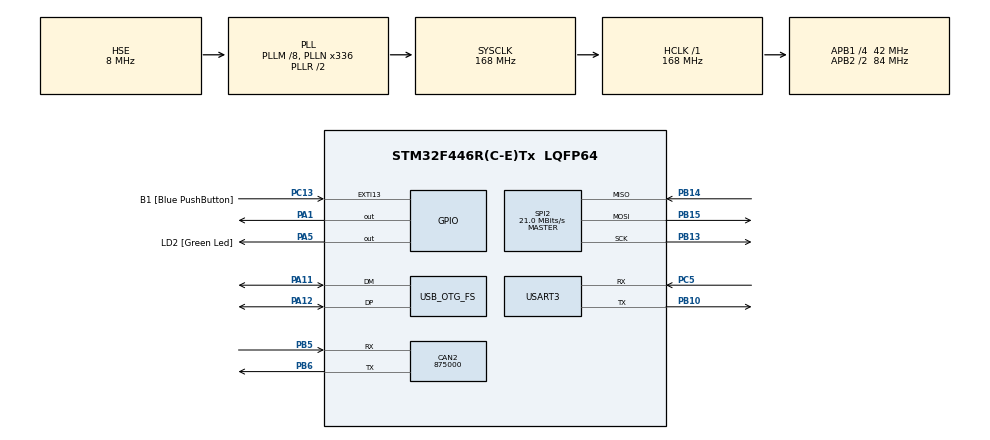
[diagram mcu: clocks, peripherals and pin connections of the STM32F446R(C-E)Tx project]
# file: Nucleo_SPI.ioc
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CAN2.CalculateBaudRate=875000
CAN2.CalculateTimeBit=1142
CAN2.CalculateTimeQuantum=380.95238095238096
Mcu.Family=STM32F4
Mcu.Name=STM32F446R(C-E)Tx
Mcu.Package=LQFP64
NVIC.PriorityGroup=NVIC_PRIORITYGROUP_0
PA1.Signal=GPIO_Output
PA11.Mode=Device_Only
PA11.Signal=USB_OTG_FS_DM
PA12.Mode=Device_Only
PA12.Signal=USB_OTG_FS_DP
PA13.GPIO_Label=TMS
PA13.Mode=Serial_Wire
PA13.Signal=SYS_JTMS-SWDIO
PA14.GPIO_Label=TCK
PA14.Mode=Serial_Wire
PA14.Signal=SYS_JTCK-SWCLK
PA2.GPIO_Label=USART_TX
PA2.Signal=USART2_TX
PA3.GPIO_Label=USART_RX
PA3.Signal=USART2_RX
PA5.GPIO_Label=LD2 [Green Led]
PA5.Signal=GPIO_Output
PB10.Mode=Asynchronous
PB10.Signal=USART3_TX
PB13.Mode=Full_Duplex_Master
PB13.Signal=SPI2_SCK
PB14.Mode=Full_Duplex_Master
PB14.Signal=SPI2_MISO
PB15.Mode=Full_Duplex_Master
PB15.Signal=SPI2_MOSI
PB3.GPIO_Label=SWO
PB3.Signal=SYS_JTDO-SWO
PB5.Mode=CAN_Activate
PB5.Signal=CAN2_RX
PB6.Mode=CAN_Activate
PB6.Signal=CAN2_TX
PC13.GPIO_Label=B1 [Blue PushButton]
PC13.GPIO_ModeDefaultEXTI=GPIO_MODE_IT_FALLING
PC13.Signal=GPXTI13
PC14-OSC32_IN.Mode=LSE-External-Oscillator
PC14-OSC32_IN.Signal=RCC_OSC32_IN
PC15-OSC32_OUT.Mode=LSE-External-Oscillator
PC15-OSC32_OUT.Signal=RCC_OSC32_OUT
PC5.Mode=Asynchronous
PC5.Signal=USART3_RX
PH0-OSC_IN.Mode=HSE-External-Oscillator
PH0-OSC_IN.Signal=RCC_OSC_IN
PH1-OSC_OUT.Mode=HSE-External-Oscillator
PH1-OSC_OUT.Signal=RCC_OSC_OUT
ProjectManager.HeapSize=0x200
ProjectManager.StackSize=0x400
ProjectManager.TargetToolchain=EWARM V8.50
RCC.48MHZClocksFreq_Value=84000000
RCC.AHBFreq_Value=168000000
RCC.APB1CLKDivider=RCC_HCLK_DIV4
RCC.APB1Freq_Value=42000000
RCC.APB1TimFreq_Value=84000000
RCC.APB2CLKDivider=RCC_HCLK_DIV2
RCC.APB2Freq_Value=84000000
RCC.APB2TimFreq_Value=168000000
RCC.CortexFreq_Value=168000000
RCC.FLatency-AdvancedSettings=FLASH_LATENCY_5
RCC.HCLKFreq_Value=168000000
RCC.HSE_VALUE=8000000
RCC.HSI_VALUE=16000000
RCC.PLLM=8
RCC.PLLN=336
RCC.PLLQ=7
RCC.SYSCLKFreq_VALUE=168000000
RCC.SYSCLKSource=RCC_SYSCLKSOURCE_PLLRCLK
RCC.USBFreq_Value=48000000
RCC.VCOOutputFreq_Value=336000000
SPI2.CalculateBaudRate=21.0 MBits/s
SPI2.Direction=SPI_DIRECTION_2LINES
SPI2.Mode=SPI_MODE_MASTER
SPI2.VirtualType=VM_MASTER
TIM10.Period=5000-1
TIM10.Prescaler=168-1
USART3.VirtualMode=VM_ASYNC
USB_OTG_FS.VirtualMode=Device_Only
VP_TIM10_VS_ClockSourceINT.Mode=Enable_Timer
board=NUCLEO-F446RE

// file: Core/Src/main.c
/* USER CODE BEGIN Header */
/**
  ******************************************************************************
  * @file           : main.c
  * @brief          : Main program body
  ******************************************************************************
  * @attention
  *
  * Copyright (c) 2026 STMicroelectronics.
  * All rights reserved.
  *
  * This software is licensed under terms that can be found in the LICENSE file
  * in the root directory of this software component.
  * If no LICENSE file comes with this software, it is provided AS-IS.
  *
  ******************************************************************************
  */
/* USER CODE END Header */
#include "main.h"

CAN_HandleTypeDef hcan2;

SPI_HandleTypeDef hspi2;

UART_HandleTypeDef huart3;

PCD_HandleTypeDef hpcd_USB_OTG_FS;

void SystemClock_Config(void);
static void MX_GPIO_Init(void);
static void MX_CAN2_Init(void);
static void MX_SPI2_Init(void);
static void MX_USART3_UART_Init(void);
static void MX_USB_OTG_FS_PCD_Init(void);
static void MX_TIM10_Init(void);

int main(void)
{

  /* MCU Configuration--------------------------------------------------------*/

  /* Reset of all peripherals, Initializes the Flash interface and the Systick. */
  HAL_Init();

  /* Configure the system clock */
  SystemClock_Config();

  /* Initialize all configured peripherals */
  MX_GPIO_Init();
  MX_CAN2_Init();
  MX_SPI2_Init();
  MX_USART3_UART_Init();
  MX_USB_OTG_FS_PCD_Init();
  MX_TIM10_Init();
  /* USER CODE BEGIN 2 */
  /*
  odrv0.onFeedback(onFeedback, &odrv0_user_data);
  odrv0.onStatus(onHeartbeat, &odrv0_user_data);

    // --- Configure CAN Filter ---

    CAN_FilterTypeDef sFilterConfig;

    sFilterConfig.FilterBank = 0;

    sFilterConfig.FilterMode = CAN_FILTERMODE_IDMASK;

    sFilterConfig.FilterScale = CAN_FILTERSCALE_32BIT;

    sFilterConfig.FilterIdHigh = 0x0000;

    sFilterConfig.FilterIdLow = 0x0000;

    sFilterConfig.FilterMaskIdHigh = 0x0000;

    sFilterConfig.FilterMaskIdLow = 0x0000; // Accept all messages

    sFilterConfig.FilterFIFOAssignment = CAN_RX_FIFO0;

    sFilterConfig.FilterActivation = ENABLE;

    if (HAL_CAN_ConfigFilter(&hcan1, &sFilterConfig) != HAL_OK) {
  	//printf("ERROR Filter \r\n");
  	Error_Handler();
    }

    // --- Start CAN Peripheral ---

    if (HAL_CAN_Start(&hcan1) != HAL_OK) {
  	//printf("ERROR CAN \r\n");
  	Error_Handler();
    }

    if (HAL_CAN_ActivateNotification(&hcan1, CAN_IT_RX_FIFO0_MSG_PENDING) != HAL_OK) {
  	//printf("ERROR CAN_2 \r\n");
  	  Error_Handler();
    }

    // --- Wait for ODrive ---

    //printf("ODrive Wait \r\n");

    while (!odrv0_user_data.received_heartbeat) {
  	pumpEvents(can_intf); // Check for messages
  	HAL_Delay(100); // Wait 100ms
    }

    //printf("ODrive Found \r\n");

    // --- Request Bus Voltage ---

    Get_Bus_Voltage_Current_msg_t vbus;

    if (!odrv0.request(vbus, 1000)) {
  	//printf("Vbus Fail \r\n");
  	Error_Handler();
    }
    */

    LL_TIM_SetCounter(TIM10, 0);
    LL_TIM_EnableIT_UPDATE(TIM10);
    LL_TIM_EnableCounter(TIM10);
  /* USER CODE END 2 */

  /* Infinite loop */
  while (1)
  {

  }
}

void SystemClock_Config(void)
{
  RCC_OscInitTypeDef RCC_OscInitStruct = {0};
  RCC_ClkInitTypeDef RCC_ClkInitStruct = {0};

  /** Configure the main internal regulator output voltage
  */
  __HAL_RCC_PWR_CLK_ENABLE();
  __HAL_PWR_VOLTAGESCALING_CONFIG(PWR_REGULATOR_VOLTAGE_SCALE1);

  /** Initializes the RCC Oscillators according to the specified parameters
  * in the RCC_OscInitTypeDef structure.
  */
  RCC_OscInitStruct.OscillatorType = RCC_OSCILLATORTYPE_HSE;
  RCC_OscInitStruct.HSEState = RCC_HSE_ON;
  RCC_OscInitStruct.PLL.PLLState = RCC_PLL_ON;
  RCC_OscInitStruct.PLL.PLLSource = RCC_PLLSOURCE_HSE;
  RCC_OscInitStruct.PLL.PLLM = 8;
  RCC_OscInitStruct.PLL.PLLN = 336;
  RCC_OscInitStruct.PLL.PLLP = RCC_PLLP_DIV2;
  RCC_OscInitStruct.PLL.PLLQ = 7;
  RCC_OscInitStruct.PLL.PLLR = 2;
  if (HAL_RCC_OscConfig(&RCC_OscInitStruct) != HAL_OK)
  {
    Error_Handler();
  }

  /** Initializes the CPU, AHB and APB buses clocks
  */
  RCC_ClkInitStruct.ClockType = RCC_CLOCKTYPE_HCLK|RCC_CLOCKTYPE_SYSCLK
                              |RCC_CLOCKTYPE_PCLK1|RCC_CLOCKTYPE_PCLK2;
  RCC_ClkInitStruct.SYSCLKSource = RCC_SYSCLKSOURCE_PLLRCLK;
  RCC_ClkInitStruct.AHBCLKDivider = RCC_SYSCLK_DIV1;
  RCC_ClkInitStruct.APB1CLKDivider = RCC_HCLK_DIV4;
  RCC_ClkInitStruct.APB2CLKDivider = RCC_HCLK_DIV2;

  if (HAL_RCC_ClockConfig(&RCC_ClkInitStruct, FLASH_LATENCY_5) != HAL_OK)
  {
    Error_Handler();
  }
}

static void MX_CAN2_Init(void)
{

  hcan2.Instance = CAN2;
  hcan2.Init.Prescaler = 16;
  hcan2.Init.Mode = CAN_MODE_NORMAL;
  hcan2.Init.SyncJumpWidth = CAN_SJW_1TQ;
  hcan2.Init.TimeSeg1 = CAN_BS1_1TQ;
  hcan2.Init.TimeSeg2 = CAN_BS2_1TQ;
  hcan2.Init.TimeTriggeredMode = DISABLE;
  hcan2.Init.AutoBusOff = DISABLE;
  hcan2.Init.AutoWakeUp = DISABLE;
  hcan2.Init.AutoRetransmission = DISABLE;
  hcan2.Init.ReceiveFifoLocked = DISABLE;
  hcan2.Init.TransmitFifoPriority = DISABLE;
  if (HAL_CAN_Init(&hcan2) != HAL_OK)
  {
    Error_Handler();
  }

}

static void MX_SPI2_Init(void)
{

  /* SPI2 parameter configuration*/
  hspi2.Instance = SPI2;
  hspi2.Init.Mode = SPI_MODE_MASTER;
  hspi2.Init.Direction = SPI_DIRECTION_2LINES;
  hspi2.Init.DataSize = SPI_DATASIZE_8BIT;
  hspi2.Init.CLKPolarity = SPI_POLARITY_LOW;
  hspi2.Init.CLKPhase = SPI_PHASE_1EDGE;
  hspi2.Init.NSS = SPI_NSS_SOFT;
  hspi2.Init.BaudRatePrescaler = SPI_BAUDRATEPRESCALER_2;
  hspi2.Init.FirstBit = SPI_FIRSTBIT_MSB;
  hspi2.Init.TIMode = SPI_TIMODE_DISABLE;
  hspi2.Init.CRCCalculation = SPI_CRCCALCULATION_DISABLE;
  hspi2.Init.CRCPolynomial = 10;
  if (HAL_SPI_Init(&hspi2) != HAL_OK)
  {
    Error_Handler();
  }

}

static void MX_TIM10_Init(void)
{

  LL_TIM_InitTypeDef TIM_InitStruct = {0};

  /* Peripheral clock enable */
  LL_APB2_GRP1_EnableClock(LL_APB2_GRP1_PERIPH_TIM10);

  TIM_InitStruct.Prescaler = 167;
  TIM_InitStruct.CounterMode = LL_TIM_COUNTERMODE_UP;
  TIM_InitStruct.Autoreload = 5000-LL_TIM_IC_FILTER_FDIV1_N2;
  TIM_InitStruct.ClockDivision = LL_TIM_CLOCKDIVISION_DIV1;
  LL_TIM_Init(TIM10, &TIM_InitStruct);
  LL_TIM_DisableARRPreload(TIM10);

}

static void MX_USART3_UART_Init(void)
{

  huart3.Instance = USART3;
  huart3.Init.BaudRate = 115200;
  huart3.Init.WordLength = UART_WORDLENGTH_8B;
  huart3.Init.StopBits = UART_STOPBITS_1;
  huart3.Init.Parity = UART_PARITY_NONE;
  huart3.Init.Mode = UART_MODE_TX_RX;
  huart3.Init.HwFlowCtl = UART_HWCONTROL_NONE;
  huart3.Init.OverSampling = UART_OVERSAMPLING_16;
  if (HAL_UART_Init(&huart3) != HAL_OK)
  {
    Error_Handler();
  }

}

static void MX_USB_OTG_FS_PCD_Init(void)
{

  hpcd_USB_OTG_FS.Instance = USB_OTG_FS;
  hpcd_USB_OTG_FS.Init.dev_endpoints = 6;
  hpcd_USB_OTG_FS.Init.speed = PCD_SPEED_FULL;
  hpcd_USB_OTG_FS.Init.dma_enable = DISABLE;
  hpcd_USB_OTG_FS.Init.phy_itface = PCD_PHY_EMBEDDED;
  hpcd_USB_OTG_FS.Init.Sof_enable = DISABLE;
  hpcd_USB_OTG_FS.Init.low_power_enable = DISABLE;
  hpcd_USB_OTG_FS.Init.lpm_enable = DISABLE;
  hpcd_USB_OTG_FS.Init.vbus_sensing_enable = DISABLE;
  hpcd_USB_OTG_FS.Init.use_dedicated_ep1 = DISABLE;
  if (HAL_PCD_Init(&hpcd_USB_OTG_FS) != HAL_OK)
  {
    Error_Handler();
  }

}

static void MX_GPIO_Init(void)
{
  GPIO_InitTypeDef GPIO_InitStruct = {0};

  /* GPIO Ports Clock Enable */
  __HAL_RCC_GPIOC_CLK_ENABLE();
  __HAL_RCC_GPIOH_CLK_ENABLE();
  __HAL_RCC_GPIOA_CLK_ENABLE();
  __HAL_RCC_GPIOB_CLK_ENABLE();

  /*Configure GPIO pin Output Level */
  HAL_GPIO_WritePin(GPIOA, GPIO_PIN_1|LD2_Pin, GPIO_PIN_RESET);

  /*Configure GPIO pin : B1_Pin */
  GPIO_InitStruct.Pin = B1_Pin;
  GPIO_InitStruct.Mode = GPIO_MODE_IT_FALLING;
  GPIO_InitStruct.Pull = GPIO_NOPULL;
  HAL_GPIO_Init(B1_GPIO_Port, &GPIO_InitStruct);

  /*Configure GPIO pins : PA1 LD2_Pin */
  GPIO_InitStruct.Pin = GPIO_PIN_1|LD2_Pin;
  GPIO_InitStruct.Mode = GPIO_MODE_OUTPUT_PP;
  GPIO_InitStruct.Pull = GPIO_NOPULL;
  GPIO_InitStruct.Speed = GPIO_SPEED_FREQ_LOW;
  HAL_GPIO_Init(GPIOA, &GPIO_InitStruct);

  /*Configure GPIO pins : USART_TX_Pin USART_RX_Pin */
  GPIO_InitStruct.Pin = USART_TX_Pin|USART_RX_Pin;
  GPIO_InitStruct.Mode = GPIO_MODE_AF_PP;
  GPIO_InitStruct.Pull = GPIO_NOPULL;
  GPIO_InitStruct.Speed = GPIO_SPEED_FREQ_VERY_HIGH;
  GPIO_InitStruct.Alternate = GPIO_AF7_USART2;
  HAL_GPIO_Init(GPIOA, &GPIO_InitStruct);

}

void Error_Handler(void)
{
  __disable_irq();
  while (1)
  {
  }
}
